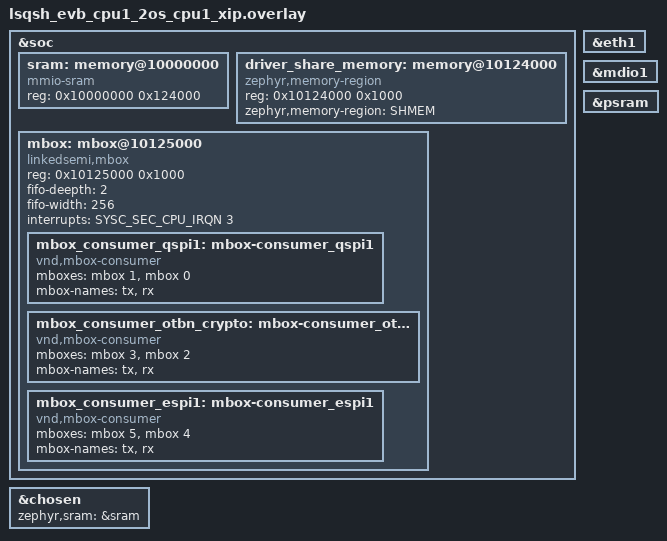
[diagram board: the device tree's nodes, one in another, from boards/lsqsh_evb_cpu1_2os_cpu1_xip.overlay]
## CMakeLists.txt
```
cmake_minimum_required(VERSION 3.20.0)

set(TOOLCHAIN_HAS_NEWLIB y)

find_package(Zephyr REQUIRED HINTS $ENV{ZEPHYR_BASE})

project(bmc_app LANGUAGES C CXX)

target_sources(app PRIVATE main.c
    dbus/sd-bus.c
    dbus/sd-event.c
    dbus/sd-journal.c
    misc.c)
zephyr_include_directories(inc)
zephyr_linker_sources(SECTIONS ipmid_section.ld)
```

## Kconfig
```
config INTERNAL_CONFIG
    bool
    default y
    select RISCV_ISA_EXT_F
    select CPU_HAS_FPU
    select FPU

source "Kconfig.zephyr"
```

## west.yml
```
manifest:

  remotes:
    - name: linkedsemi
      url-base: https://github.com/linkedsemi
  projects:
    - name: zephyr
      remote: linkedsemi
      revision: 9aba231538cb15e326d0b32fb71ca6ec78597236
      import:
        name-allowlist:
          - fatfs
          - littlefs
    - name: ls_sdk
      revision: 8e480881e7888d80db16ccb5c70e5a515f84650c
      remote: linkedsemi
      path: modules/hal/linkedsemi
      groups:
        - hal
    - name: mbedtls
      revision: a8be860ee1686013afd1fa27435d87b56c1f60d9
      remote: linkedsemi
      path: modules/crypto/mbedtls
      groups:
        - crypto
    - name: wolfssl
      revision: 89450e806ffa6cedd4f12fbf725acd990ac38320
      remote: linkedsemi
      path: modules/lib/wolfssl
    - name: wolfssh
      revision: fe25b4ef99eccb63ceec62f9948b6325dc279099
      remote: linkedsemi
      path: modules/lib/wolfssh
    - name: safeclib
      revision: 4e279a5254d7e443e3659fec95cf25ceaa4c8a27
      remote: linkedsemi
      path: modules/safeclib
    - name: jtag_asd
      revision: 9bf8e9ca6a7e28fb6f33758f0c463f358b16ad28
      remote: linkedsemi
      path: modules/jtag_asd
    - name: basu
      revision: 882fe5b94a8847edfe996d54bbfb0844d98a51d0
      remote: linkedsemi
      path: modules/lib/basu
    - name: dbus-broker
      revision: 393c86f08e7303c44ae71f3970fc29adf63d95c8
      remote: linkedsemi
      path: modules/lib/dbus-broker
    - name: nlohmann_json
      revision: 21d6a8608dd486b3bdc69b5f3f36f4c2e32ea462
      remote: linkedsemi
      path: openbmc/nlohmann_json
    - name: phosphor-host-ipmid
      revision: 730b99eceb20ac83a155bb5b3ebfe294fbad685a
      remote: linkedsemi
      path: openbmc/phosphor-host-ipmid
    - name: boost
      revision: ecb994e4dd073c20249af3570d365cce79d9095c
      remote: linkedsemi
      path: openbmc/boost
    - name: sdeventplus
      revision: b08defd63ee0cc1272ab325254607e02b27fb972
      remote: linkedsemi
      path: openbmc/sdeventplus
    - name: stdplus
      revision: e7e5ac6c2a5b0a7abdfca49fa8bdeea58451292d
      remote: linkedsemi
      path: openbmc/stdplus
    - name: fmt
      revision: 7efd053646053b98a7b4426e89f9661ba0de20e1
      remote: linkedsemi
      path: openbmc/fmt
    - name: function2
      revision: c06f8813e86649f7400046a25994d462fe5ff7b9
      remote: linkedsemi
      path: openbmc/function2
    - name: sdbusplus
      revision: 8509238c2e8602a706666208fbc088f3c9c3d326
      remote: linkedsemi
      path: openbmc/sdbusplus
    - name: phosphor-logging
      revision: 3238acdf4dbc14b1cb62a90739becdaf0bc66402
      remote: linkedsemi
      path: openbmc/phosphor-logging
    - name: phosphor-dbus-interfaces
      revision: b9c6138f7646f4cd10374600386552bf905eb68d
      remote: linkedsemi
      path: openbmc/phosphor-dbus-interfaces
    - name: phosphor-objmgr
      revision: 7d4eb7772eb67e8a57bb9dab55dfcbd362e3c6bb
      remote: linkedsemi
      path: openbmc/phosphor-objmgr
    - name: zephyr-osal
      revision: 47fe85a8680038272ac783a4ce8f4cdcb51b40a6
      remote: linkedsemi
      path: openbmc/zephyr-osal
    - name: tinyxml2
      revision: 19970f901fc80455e6fb5c15c26c197a6219578d
      remote: linkedsemi
      path: openbmc/tinyxml2
    - name: phosphor-net-ipmid
      revision: 245cd64dec52e85913267071df907d8395189934
      remote: linkedsemi
      path: openbmc/phosphor-net-ipmid
    - name: valijson
      revision: 94adf049ae196e127f3df0c18a1fefec9aa91ffd
      remote: linkedsemi
      path: openbmc/valijson
    - name: entity-manager
      revision: 3b91d98a54b7d59a5b8e6adf31a0a08fa84fd3d5
      remote: linkedsemi
      path: openbmc/entity-manager
    - name: i2c-tools
      revision: 0f412d81bb96408c383e7975b43cae2acab0199a
      remote: linkedsemi
      path: openbmc/i2c-tools
    - name: mk-rofs
      revision: a9d799835340258a4e0324e7b765dc860702b5a5
      remote: linkedsemi
      path: openbmc/mk-rofs
    - name: ipmitool
      revision: 0612d2f435143068074414a8bbdb54e7abf89e20
      remote: linkedsemi
      path: openbmc/ipmitool
    - name: kcsbridge
      revision: c75e6c1a14152f822f769fd8a38f691390cbfa2e
      remote: linkedsemi
      path: openbmc/kcsbridge
    - name: zephyr-devfs
      revision: a8cd40c478183bf0542fe570a45c07ee4688e513
      remote: linkedsemi
      path: openbmc/zephyr-devfs
    - name: dbus-sensors
      revision: 406c04ee7f4f0963600f638b2547e835e1ebf05a
      remote: linkedsemi
      path: openbmc/dbus-sensors
    - name: libgpiod
      revision: a75d5b0ff8d1554dd5bc5c78c2892b5d58dc28da
      remote: linkedsemi
      path: openbmc/libgpiod
    - name: cereal
      revision: b649d13a60f52f66a5c2f01b23ac5dac4ea703fb
      remote: linkedsemi
      path: openbmc/cereal
    - name: bmcweb
      revision: 933053b7a557adbb325d8f68f5d25c68a0ce82bf
      remote: linkedsemi
      path: openbmc/bmcweb
    - name: cli11
      revision: 94def1d7ee59c2ff2bb6b284c826e76cd1b1792a
      remote: linkedsemi
      path: openbmc/cli11
    - name: webui-vue
      revision: c2d6ca1c9c56700164f07434f7384c942c977059
      remote: linkedsemi
      path: openbmc/webui-vue
    - name: phosphor-bmc-code-mgt
      revision: 13d007b1e64cc597133381d6bc899c025264d0fe
      remote: linkedsemi
      path: openbmc/phosphor-bmc-code-mgt
    - name: miniz
      revision: 659f53cf6b6da3e7c5e2b3be0076b21ef154e787
      remote: linkedsemi
      path: modules/lib/miniz
    - name: phosphor-sel-logger
      revision: 5ce58ed2b2a734409daf32be078f2fdbf5f2fb6c
      remote: linkedsemi
      path: openbmc/phosphor-sel-logger
```

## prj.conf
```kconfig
######################################################
# COMMON CONFIGURATION
######################################################
CONFIG_NEWLIB_LIBC=y
CONFIG_FILE_SYSTEM=y
CONFIG_POSIX_API=y
CONFIG_EVENTFD=y
CONFIG_LOG=n
CONFIG_STATIC_INIT_GNU=y
CONFIG_TEST_RANDOM_GENERATOR=y
CONFIG_NETWORKING=y
CONFIG_NET_TCP=y
CONFIG_NET_SOCKETS=y
CONFIG_NET_SOCKETS_POLL_MAX=4
CONFIG_MAX_PTHREAD_MUTEX_COUNT=128


CONFIG_NET_ZPERF=y
# CONFIG_NET_LOG is not set
CONFIG_NET_UDP=y
# NET_IPV6=n 时该选项无依赖，置 n 避免 Kconfig 警告
CONFIG_NET_TCP_IPV6_ND_REACHABILITY_HINT=n
CONFIG_NET_STATISTICS=y
CONFIG_NET_STATISTICS_USER_API=y
CONFIG_NET_STATISTICS_IPV4=y
CONFIG_NET_STATISTICS_UDP=y
CONFIG_NET_STATISTICS_TCP=y
CONFIG_NET_STATISTICS_ETHERNET=y
CONFIG_NET_TC_TX_COUNT=1
CONFIG_NET_SOCKETS_SERVICE_THREAD_PRIO=-1
CONFIG_INIT_STACKS=y
CONFIG_NET_L2_ETHERNET=y

# Shell enabled with serial backend
CONFIG_SHELL=y
CONFIG_KERNEL_SHELL=y
CONFIG_SHELL_BACKEND_SERIAL=y
CONFIG_SHELL_THREAD_PRIORITY_OVERRIDE=y
CONFIG_NET_SHELL=y
CONFIG_SPEED_OPTIMIZATIONS=y

######################################################
# 网络配置（参考 zephyr_openbmc - 仅 IPv4）
######################################################
CONFIG_NET_IPV4=y
CONFIG_NET_IPV6=n


CONFIG_NET_CONFIG_SETTINGS=y
CONFIG_NET_CONFIG_AUTO_INIT=n
CONFIG_NET_CONFIG_INIT_TIMEOUT=120

CONFIG_NET_DHCPV4=y
CONFIG_NET_CONFIG_MY_IPV4_ADDR="192.0.2.13"
CONFIG_NET_CONFIG_MY_IPV4_NETMASK="255.255.255.0"
CONFIG_NET_CONFIG_MY_IPV4_GW=""


CONFIG_NET_IF_UNICAST_IPV4_ADDR_COUNT=2

# ARP 协议
CONFIG_NET_ARP=y
CONFIG_NET_ARP_GRATUITOUS=y
CONFIG_NET_ARP_GRATUITOUS_TRANSMISSION=y
CONFIG_NET_MGMT_EVENT_INFO=y

CONFIG_NET_IPV4_ACD=y



# CONFIG_NET_CORE_LOG_LEVEL_DBG=y
# CONFIG_NET_ARP_LOG_LEVEL_DBG=y
# CONFIG_NET_L2_ETHERNET_LOG_LEVEL_DBG=y
# CONFIG_NET_ICMPV4_LOG_LEVEL_DBG=y
# CONFIG_NET_IF_LOG_LEVEL_DBG=y
# CONFIG_NET_CONFIG_LOG_LEVEL_DBG=y


CONFIG_NET_TCP_WORKER_PRIO=10

# 网络管理
CONFIG_NET_MGMT=y
CONFIG_NET_MGMT_EVENT=y
CONFIG_NET_L2_ETHERNET_MGMT=y


CONFIG_NET_BUF_DATA_SIZE=256
CONFIG_NET_PKT_RX_COUNT=64
CONFIG_NET_PKT_TX_COUNT=64
CONFIG_NET_BUF_RX_COUNT=128
CONFIG_NET_BUF_TX_COUNT=128
CONFIG_NET_MAX_CONTEXTS=32
CONFIG_NET_MAX_CONN=32

# 网络栈大小配置
CONFIG_NET_TX_STACK_SIZE=2048
CONFIG_NET_RX_STACK_SIZE=2048
CONFIG_NET_MGMT_EVENT_STACK_SIZE=3072

CONFIG_NET_LOOPBACK=y


CONFIG_NET_IF_UNICAST_IPV4_ADDR_COUNT=2
CONFIG_NET_IF_MCAST_IPV4_ADDR_COUNT=1

CONFIG_NET_CONTEXT_RECV_PKTINFO=y

CONFIG_THREAD_NAME=y

CONFIG_TEST_AUTH=y
######################################################
# INET SOCKETS CONFIGURATION
######################################################
# CONFIG_NET_LOOPBACK=y
# CONFIG_NET_IPV4=y
# CONFIG_NET_SOCKETS_PACKET=y
# CONFIG_NET_MAX_CONTEXTS=32
# CONFIG_NET_MAX_CONN=32
# CONFIG_NET_PKT_RX_COUNT=64
# CONFIG_NET_PKT_TX_COUNT=64
# CONFIG_NET_BUF_RX_COUNT=128
# CONFIG_NET_BUF_TX_COUNT=128
######################################################
# INET SOCKETS CONFIGURATION END
######################################################


############################################
# UNIX SOCKET DBUS BROKER CONFIGURATION
#Test Target	SOCKETPOOL_SIZE	BUFFER_SIZE	HEAP_SIZE	Max Connections
# 10  clients	    16	            8192	  256KB	          ~10
# 20  clients	    32	            16384	  512KB	          ~20
# 50  clients	    64	            16384	   1MB	        ~40-50
# 100 clients	    128	            32768	   2MB	        ~80-100
############################################
CONFIG_PSRAM=y
CONFIG_NEWLIB_LIBC_MALLOC_SECTION_NAME="PSRAM"
CONFIG_NEWLIB_LIBC_MALLOC_LSQSH=y

CONFIG_SYS_HEAP_RUNTIME_STATS=y

CONFIG_NEWLIB_LIBC_MALLOC_ARENA_SIZE=5242880

CONFIG_MAIN_STACK_SIZE=102400
CONFIG_HEAP_MEM_POOL_SIZE=212992
CONFIG_POSIX_MAX_FDS=112
CONFIG_ZVFS_POLL_MAX=112
CONFIG_ZVFS_OPEN_MAX=80
CONFIG_NET_SOCKETPAIR=y
CONFIG_NET_SOCKETPAIR_BUFFER_SIZE=4096
######################################################
# DBUS SOCKET MODE SELECTION
######################################################
# Enable D-Bus broker subsystem
CONFIG_DBROKER=y
CONFIG_DBUS_BROKER_STACK_SIZE=6144
CONFIG_DBUS_BROKER_PRIORITY=7
# UNIX domain sockets
CONFIG_DBUS_BROKER_SOCKETPOOL=y
CONFIG_DBUS_BROKER_SOCKETPOOL_SIZE=16
CONFIG_DBUS_BROKER_SOCKETPOOL_BUFFER_SIZE=6144
# INET sockets
# CONFIG_DBUS_BROKER_INET=y
# CONFIG_DBUS_BROKER_PORT=55555

CONFIG_ASSERT=y

CONFIG_XIP=y
CONFIG_BOOT_CPU2=n
# CONFIG_THREAD_LOCAL_STORAGE=y
# CONFIG_LOG_DEFAULT_LEVEL=3
CONFIG_FRAME_POINTER=y
CONFIG_THREAD_LOCAL_STORAGE=y
CONFIG_TOOLCHAIN_CROSS_COMPILE_SUPPORTS_THREAD_LOCAL_STORAGE=y
CONFIG_POSIX_THREADS=y

CONFIG_ZVFS_OPEN_MAX=512
CONFIG_ZVFS_EVENTFD_MAX=512

CONFIG_CPP=y
CONFIG_STD_CPP20=y
CONFIG_REQUIRES_FULL_LIBCPP=y
CONFIG_CPP_EXCEPTIONS=y
CONFIG_TOOLCHAIN_CROSS_COMPILE_SUPPORTS_GNU_EXTENSIONS=y



CONFIG_POSIX_THREAD_THREADS_MAX=40
CONFIG_POSIX_TIMERS=y
CONFIG_XOPEN_STREAMS=y
CONFIG_CPP_RTTI=y

CONFIG_BASU=y
CONFIG_DBUS_BROKER=y
# CONFIG_NET_DEBUG=y
CONFIG_ZEPHYR_OSAL=y

CONFIG_NET_HOSTNAME="openbmc"
CONFIG_NET_HOSTNAME_DYNAMIC=y

CONFIG_OPENBMC_SDBUSPLUS=y

CONFIG_OPENBMC_PHOSPHOR_HOST_IPMID=y
CONFIG_OPENBMC_PHOSPHOR_NET_IPMID=y

CONFIG_OPENBMC_BOOST=y

CONFIG_OPENBMC_PHOSPHOR_LOGGING=y

CONFIG_OPENBMC_PHOSPHOR_OBJMGR=y

CONFIG_TINYXML2=y

CONFIG_WOLFSSL=y
CONFIG_WOLFSSL_SETTINGS_FILE="wolfssl_user_settings.h"

CONFIG_OPENBMC_PHOSPHOR_DBUS_INTERFACES=y

CONFIG_OPENBMC_SDEVENTPLUS=y



# debug config
# CONFIG_HW_STACK_PROTECTION=y
# CONFIG_PMP_STACK_GUARD_MIN_SIZE=2048
```

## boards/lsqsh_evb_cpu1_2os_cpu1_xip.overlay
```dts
&soc {
    /delete-node/ memory@100c0000;
    /delete-node/ memory@10100000;
    /delete-node/ memory@100be000;
    /delete-node/ mbox@100bf000;
    sram: memory@10000000 {
        compatible = "mmio-sram";
        reg = <0x10000000 0x124000>;
    };
    driver_share_memory: memory@10124000 {
        compatible = "zephyr,memory-region", "mmio-sram";
        reg = <0x10124000 0x1000>;
        zephyr,memory-region = "SHMEM";
    };
    mbox: mbox@10125000 {
        compatible = "linkedsemi,mbox";
        reg = <0x10125000 0x1000>;
        fifo-deepth = <2>;
        fifo-width = <256>;
        #mbox-cells = <1>;
        interrupts = <SYSC_SEC_CPU_IRQN 3>;
        status = "okay";
        mbox_consumer_qspi1: mbox-consumer_qspi1 {
            compatible = "vnd,mbox-consumer";
            mboxes = <&mbox 1>, <&mbox 0>;
            mbox-names = "tx", "rx";
        };
        mbox_consumer_otbn_crypto: mbox-consumer_otbn_crypto {
            compatible = "vnd,mbox-consumer";
            mboxes = <&mbox 3>, <&mbox 2>;
            mbox-names = "tx", "rx";
        };
        mbox_consumer_espi1: mbox-consumer_espi1 {
            compatible = "vnd,mbox-consumer";
            mboxes = <&mbox 5>, <&mbox 4>;
            mbox-names = "tx", "rx";
        };
    };
};


&chosen {
    zephyr,sram = &sram;
};

&eth1 {
    status = "okay";
};

&mdio1 {
    status = "okay";
};


&psram {
    status = "okay";
};
```

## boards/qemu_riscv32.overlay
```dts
/ {
	chosen {
		zephyr,uart_pipe = &uart0;
	};
};
```

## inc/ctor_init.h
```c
#ifndef CTOR_INIT_H_
#define CTOR_INIT_H_
#include <zephyr/sys/iterable_sections.h>
typedef void (*ctor_fn_t)();
#define CTOR_SECTION_ITERABLE(secname,func) \
    const static TYPE_SECTION_ITERABLE(ctor_fn_t,func##_ptr,secname,func##_ptr) = func;

#endif
```

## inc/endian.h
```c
#ifndef ENDIAN_H_
#define ENDIAN_H_
#include <stdint.h>

uint16_t htobe16(uint16_t host_16bits);
static inline uint16_t htole16(uint16_t host_16bits)
{
    return host_16bits;
}

uint16_t be16toh(uint16_t big_endian_16bits);
static inline uint16_t le16toh(uint16_t little_endian_16bits)
{
    return little_endian_16bits;
}

uint32_t htobe32(uint32_t host_32bits);

static inline uint32_t htole32(uint32_t host_32bits)
{
	return host_32bits;
}

uint32_t be32toh(uint32_t big_endian_32bits);
static uint32_t le32toh(uint32_t little_endian_32bits)
{
    return little_endian_32bits;
}

uint64_t htobe64(uint64_t host_64bits);
uint64_t htole64(uint64_t host_64bits);
uint64_t be64toh(uint64_t big_endian_64bits);
uint64_t le64toh(uint64_t little_endian_64bits);


#endif
```

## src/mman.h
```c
#ifndef ZEPHYR_MMAN_H
#define ZEPHYR_MMAN_H

#include <stddef.h>

/* Memory protection flags */
#ifndef PROT_READ
#define PROT_READ  0x1
#endif

#ifndef PROT_WRITE
#define PROT_WRITE 0x2
#endif

#ifndef PROT_EXEC
#define PROT_EXEC  0x4
#endif

#ifndef PROT_NONE
#define PROT_NONE  0x0
#endif

/* Mapping flags */
#ifndef MAP_SHARED
#define MAP_SHARED    0x01
#endif

#ifndef MAP_PRIVATE
#define MAP_PRIVATE   0x02
#endif

#ifndef MAP_FIXED
#define MAP_FIXED     0x10
#endif

#ifndef MAP_ANONYMOUS
#define MAP_ANONYMOUS 0x20
#endif

#ifndef MAP_FAILED
#define MAP_FAILED ((void *)-1)
#endif

/* Functions declared in basu_zephyr_compat.h and implemented in sys_compat.c */
#ifdef __ZEPHYR__
void *mmap(void *addr, size_t length, int prot, int flags, int fd, off_t offset);
int munmap(void *addr, size_t length);
#endif

#endif /* ZEPHYR_MMAN_H */
```

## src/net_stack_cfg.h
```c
/* SPDX-License-Identifier: Apache-2.0 */
#pragma once

#ifdef __cplusplus
extern "C" {
#endif

int net_stack_cfg_do_once(void);

#ifdef __cplusplus
}
#endif
```

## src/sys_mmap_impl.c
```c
/* SPDX-License-Identifier: Apache-2.0 */
#include <stdlib.h>
#include <errno.h>
#include <sys/types.h>

#ifndef MAP_FAILED
#define MAP_FAILED ((void *)-1)
#endif

#ifndef MAP_ANONYMOUS
#define MAP_ANONYMOUS 0x20
#endif

#ifndef off_t
typedef long off_t;
#endif

/* Simple mmap implementation for Zephyr using malloc/free */
void *mmap(void *addr, size_t length, int prot, int flags, int fd, off_t offset)
{
	void *ptr;

	/* Zephyr doesn't support file-backed mappings */
	if (!(flags & MAP_ANONYMOUS) && fd >= 0) {
		errno = ENOSYS;
		return MAP_FAILED;
	}

	/* Ignore addr parameter - always allocate new memory */
	(void)addr;
	(void)offset;
	(void)prot;

	/* Allocate memory */
	ptr = malloc(length);
	if (!ptr) {
		errno = ENOMEM;
		return MAP_FAILED;
	}

	return ptr;
}

/* Simple munmap implementation for Zephyr using free */
int munmap(void *addr, size_t length)
{
	(void)length;

	if (!addr) {
		errno = EINVAL;
		return -1;
	}

	free(addr);
	return 0;
}
```

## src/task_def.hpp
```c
#pragma once

#include <pthread.h>

#ifdef __cplusplus
extern "C" {
#endif

#ifdef CONFIG_QEMU_TARGET
#define THREAD_STACK_SECTION
#else
// #define THREAD_STACK_SECTION(name) __attribute__((section(".noinit" "." #name "." "stack")))
#define THREAD_STACK_SECTION(name) __attribute__((section(CONFIG_APP_STACK_SECTION "." #name "." "stack")))
#endif

int create_task_with_pthread(pthread_t *thread, const char *name,
                             void *stack, size_t stack_size,
                             void* (*routine)(void *), bool join_flag);

#define CREATE_TASK_WITH_PTHREAD(thread, name, stack_size) \
    static Z_KERNEL_STACK_DEFINE_IN(name##_stack, stack_size, THREAD_STACK_SECTION(name)); \
    create_task_with_pthread(thread, #name, name##_stack, stack_size, name##_handler, false);

#define CREATE_TASK_WITH_PTHREAD_JOIN(thread, name, stack_size) \
    static Z_KERNEL_STACK_DEFINE_IN(name##_stack, stack_size, THREAD_STACK_SECTION(name)); \
    create_task_with_pthread(thread, #name, name##_stack, stack_size, name##_handler, true);

//net config init
// extern struct k_sem net_config_init_ready_sem;

// zbus broker
#define CONFIG_THREAD_PRI_DBUS_BROKER 10
#define DBUS_BROKER_THREAD_STACK_SIZE (1 * 1024)
int dbus_broker_init();
extern struct k_sem dbus_broker_ready_sem;

// phosphor-host-ipmid
#define CONFIG_THREAD_PRI_IPMI 10
#define IPMI_THREAD_STACK_SIZE (32 * 1024)
int ipmid_init();
extern struct k_sem host_ipmid_ready_sem;

// busctl
#define CONFIG_THREAD_PRI_BUSCTL 10
#define BUSCTL_THREAD_STACK_SIZE (32 * 1024)
int busctl_init();
extern struct k_sem busctl_ready_sem;

// phosphor-watchdog
#define CONFIG_THREAD_PRI_WATCHDOG 10
#define WATCHDOG_THREAD_STACK_SIZE (32 * 1024)
int watchdog_init();
extern struct k_sem watchdog_ready_sem;

// phosphor-led-sysfs
#define CONFIG_THREAD_PRI_LED_SYSFS 10
#define LED_SYSFS_THREAD_STACK_SIZE (32 * 1024)
int led_sysfs_init();
extern struct k_sem led_sysfs_ready_sem;

// phosphor-led-manager
#define CONFIG_THREAD_PRI_LED_MANAGER 10
#define LED_MANAGER_THREAD_STACK_SIZE (32 * 1024)
int led_manager_init();
extern struct k_sem led_manager_ready_sem;

// phosphor-settings
#define CONFIG_THREAD_PRI_SETTING_MANAGER 10
#define SETTING_MANAGER_THREAD_STACK_SIZE (32 * 1024)
int setting_manager_init();
extern struct k_sem setting_manager_ready_sem;

// phosphor-network
#define CONFIG_THREAD_PRI_NETWORK_MANAGER 10
#define NETWORK_MANAGER_THREAD_STACK_SIZE (32 * 1024)
int network_manager_init();
extern struct k_sem network_manager_ready_sem;

//ipmbbridge
#define CONFIG_THREAD_PRI_IPMBBRIDGE 10
#define IPMBBRIDGE_THREAD_STACK_SIZE (32 * 1024)
int ipmbbridge_init();
extern struct k_sem ipmbbridge_ready_sem;

//obmc_console
#define CONFIG_THREAD_PRI_OBMC_CONSOLE 10
#define OBMC_CONSOLE_THREAD_STACK_SIZE (32 * 1024)
int obmc_console_init();
extern struct k_sem obmc_console_ready_sem;

//timedated
#define CONFIG_THREAD_PRI_TIME_DATED 10
#define TIME_DATED_THREAD_STACK_SIZE (32 * 1024)
int timedated_init();
extern struct k_sem timedated_ready_sem;

//time-manager
#define CONFIG_THREAD_PRI_TIME_MANAGER 10
#define TIME_MANAGER_THREAD_STACK_SIZE (32 * 1024)
int time_manager_init();
extern struct k_sem time_manager_ready_sem;

//bios-setting-manager
#define CONFIG_THREAD_PRI_BIOS_SETTINGS_MGR 10
#define BIOS_SETTINGS_MGR_THREAD_STACK_SIZE (32 * 1024)
int bios_settings_mgr_init();
extern struct k_sem bios_settings_ready_sem;

//ipmitool
#define CONFIG_THREAD_PRI_IPMITOOL 10
#define IPMITOOL_THREAD_STACK_SIZE (32 * 1024)
int ipmitool_init();
extern struct k_sem ipmitool_ready_sem;

//user_manager
#define CONFIG_THREAD_PRI_USER_MANAGER 10
#define USER_MANAGER_THREAD_STACK_SIZE (32 * 1024)
int user_manager_init();
extern struct k_sem user_manager_ready_sem;

// net_stack_cfg - 网络栈配置（必须在 net-ipmid 之前初始化）
#define CONFIG_THREAD_PRI_NET_STACK_CFG 5
#define NET_STACK_CFG_THREAD_STACK_SIZE (16 * 1024)
int net_stack_cfg_init();
extern struct k_sem net_stack_cfg_ready_sem;

// phosphor-net-ipmid
#define CONFIG_THREAD_PRI_NET_IPMID 10
#define NET_IPMID_THREAD_STACK_SIZE (64 * 1024)
int net_ipmid_init();
extern struct k_sem net_ipmid_ready_sem;

//bmcweb
#define CONFIG_THREAD_PRI_BMCWEB 10
#define BMCWEB_THREAD_STACK_SIZE (32 * 1024)
int bmcweb_init();
extern struct k_sem bmcweb_ready_sem;

// phosphor-objmgr
#define CONFIG_THREAD_PRI_OBJMGR 10
#define OBJMGR_THREAD_STACK_SIZE (32 * 1024)
int objmgr_init();
extern struct k_sem objmgr_ready_sem;

// phosphor-bmc-code-mgt
#define CONFIG_THREAD_PRI_UPDATER 10
#define UPDATER_THREAD_STACK_SIZE (32 * 1024)
int software_updater_init();
extern struct k_sem software_updater_ready_sem;

#define CONFIG_THREAD_PRI_IMAGE 10
#define IMAGE_THREAD_STACK_SIZE (20 * 1024)
int image_manager_init();
extern struct k_sem image_manager_ready_sem;

//adcsensors
#define CONFIG_THREAD_PRI_ADC_SENSOR 10
#define ADC_SENSOR_THREAD_STACK_SIZE (32 * 1024)
int adc_sensor_init();
extern struct k_sem adc_sensor_ready_sem;

// phosphor-logging
#define CONFIG_THREAD_PRI_LOGGING 10
#define PHOSPHOR_LOGGING_THREAD_STACK_SIZE (32 * 1024)
int logging_init();
extern struct k_sem logging_ready_sem;

#define CONFIG_THREAD_PRI_EXTERNAL_SENSOR 10
#define EXTERNAL_SENSOR_THREAD_STACK_SIZE (32 * 1024)
int external_sensor_init();
extern struct k_sem external_sensor_ready_sem;

#define CONFIG_THREAD_PRI_FAN_SENSOR 10
#define FAN_SENSOR_THREAD_STACK_SIZE (32 * 1024)
int fan_sensor_init();
extern struct k_sem fan_sensor_ready_sem;

#define CONFIG_THREAD_PRI_HWMON_TEMP_SENSOR 10
#define HWMON_TEMP_SENSOR_THREAD_STACK_SIZE (32 * 1024)
int hwmon_temp_sensor_init();
extern struct k_sem hwmon_temp_sensor_ready_sem;

#define CONFIG_THREAD_PRI_INTEL_CPU_SENSOR 10
#define INTEL_CPU_SENSOR_THREAD_STACK_SIZE (32 * 1024)
int intel_cpu_sensor_init();
extern struct k_sem intel_cpu_sensor_ready_sem;

#define CONFIG_THREAD_PRI_INTRUSION_SENSOR 10
#define INTRUSION_SENSOR_THREAD_STACK_SIZE (32 * 1024)
int intrusion_sensor_init();
extern struct k_sem intrusion_sensor_ready_sem;

#define CONFIG_THREAD_PRI_PSU_SENSOR 10
#define PSU_SENSOR_THREAD_STACK_SIZE (32 * 1024)
int psu_sensor_init();
extern struct k_sem psu_sensor_ready_sem;

// phosphor-sel-logger
#define CONFIG_THREAD_PRI_SEL_LOGGER 10
#define SEL_LOGGER_THREAD_STACK_SIZE (32 * 1024)
int sel_logger_init();
extern struct k_sem sel_logger_ready_sem;

// phosphor-state-manager
#define CONFIG_THREAD_PRI_BMC_STATE 10
#define BMC_STATE_THREAD_STACK_SIZE (32 * 1024)
int bmc_state_init();
extern struct k_sem bmc_state_ready_sem;

// phosphor-debug-collector
#define CONFIG_THREAD_PRI_DUMP_MANAGER 10
#define DUMP_MANAGER_THREAD_STACK_SIZE (32 * 1024)
int dump_manager_init();
extern struct k_sem dump_manager_ready_sem;

// systemd-networkd
#define CONFIG_THREAD_PRI_SYSTEMD_NETWORKD 10
#define SYSTEMD_NETWORKD_THREAD_STACK_SIZE (32 * 1024)
int systemd_networkd_init();
extern struct k_sem systemd_networkd_ready_sem;

#define CONFIG_THREAD_PRI_ENTITY 10
#define ENTITY_MANAGER_THREAD_STACK_SIZE (20 * 1024)
int entity_manager_init();
extern struct k_sem entity_manager_ready_sem;

#define CONFIG_THREAD_PRI_FRU 10
#define FRU_DEVICE_THREAD_STACK_SIZE (12 * 1024)
int fru_device_init();
extern struct k_sem fru_device_ready_sem;

#define CONFIG_THREAD_PRI_CALLBACK_MANAGER 10
#define CALLBACK_MANAGER_THREAD_STACK_SIZE (32 * 1024)
int callback_manager_init();
extern struct k_sem callback_manager_ready_sem;

#define CONFIG_THREAD_PRI_PHOSPHOR_HOSTLOGGER 10
#define PHOSPHOR_HOSTLOGGER_THREAD_STACK_SIZE 64 * 1024)
int phosphor_hostlogger_init();
extern struct k_sem phosphor_hostlogger_ready_sem;

//kcs bridge
#define CONFIG_THREAD_PRI_KCS_BRIDGE 10
#define KCS_BRIDGE_THREAD_STACK_SIZE (32 * 1024)
int kcs_bridge_init();
extern struct k_sem kcs_bridge_ready_sem;

//certificate manager
#define CONFIG_THREAD_PRI_CERTIFICATE_MANAGER 10
#define CERTIFICATE_MANAGER_THREAD_STACK_SIZE (20 * 1024)
int certificate_manager_init();
extern struct k_sem certificate_manager_ready_sem;

//i2ctest
int i2ctest_init();
//kcstest
int kcstest_init();
//eepromtest
int eepromtest_init();
//gpiotest
int gpiotest_init();
//ledtest
int ledtest_init();
//uarttest
int uarttest_init();
//hwmontest
int hwmontest_init();

#ifdef __cplusplus
}
#endif
```

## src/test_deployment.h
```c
/*
 * test_deployment.h - Standard Broker Deployment Interface
 */

#ifndef TEST_DEPLOYMENT_H
#define TEST_DEPLOYMENT_H

#ifdef __cplusplus
extern "C" {
#endif

/* Main deployment function using broker_run() */
int run_broker_deployment(void);

/* Test function to verify deployment */
int test_broker_deployment(void);

int add_listener_to_broker(int listener_fd);
int create_listener_socket_with_retry(void);
int setup_controller_bus(void);

/* External variables for broker communication */
extern int g_controller_fds[2];
extern Broker *g_broker;

/* Function to start client threads */
int start_client_threads(void);

struct deployment_state {
    struct k_mutex lock;
    bool broker_ready;
    int listener_fd;
    bool service_provider_ready;
};

#ifdef __cplusplus
}
#endif

#endif /* TEST_DEPLOYMENT_H */
```

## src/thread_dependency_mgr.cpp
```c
#include "thread_dependency_mgr.hpp"

#include <string.h>
#include <zephyr/logging/log.h>

LOG_MODULE_DECLARE(TEST_BROKER, LOG_LEVEL_DBG);

// Thread registry
#define MAX_THREADS 64
static thread_descriptor_t *registered_threads[MAX_THREADS];
static int registered_thread_count = 0;
static struct k_mutex thread_registry_mutex;
static bool registry_initialized = false;

// Initialize registry
static void init_registry(void)
{
    if (!registry_initialized) {
        k_mutex_init(&thread_registry_mutex);
        registry_initialized = true;
    }
}

// Data structures for circular dependency detection
#define MAX_CALL_STACK_DEPTH 32
static const char *call_stack[MAX_CALL_STACK_DEPTH];
static int call_stack_depth = 0;
static struct k_mutex call_stack_mutex;
static bool call_stack_initialized = false;

// Initialize call stack mutex
static void init_call_stack(void)
{
    if (!call_stack_initialized) {
        k_mutex_init(&call_stack_mutex);
        call_stack_initialized = true;
    }
}

// Check for circular dependencies
static bool is_circular_dependency(const char *thread_name)
{
    for (int i = 0; i < call_stack_depth; i++) {
        if (strcmp(call_stack[i], thread_name) == 0) {
            return true;
        }
    }
    return false;
}

// Add to call stack
static bool push_call_stack(const char *thread_name)
{
    if (call_stack_depth >= MAX_CALL_STACK_DEPTH) {
        LOG_ERR("Error: Call stack overflow (max depth: %d)", MAX_CALL_STACK_DEPTH);
        return false;
    }
    call_stack[call_stack_depth++] = thread_name;
    return true;
}

// Remove from call stack
static void pop_call_stack(void)
{
    if (call_stack_depth > 0) {
        call_stack_depth--;
    }
}

void register_thread_descriptor(thread_descriptor_t *desc, const char **deps, int dep_count)
{
    init_registry();

    k_mutex_lock(&thread_registry_mutex, K_FOREVER);

    if (registered_thread_count < MAX_THREADS) {
        // Initialize dependency count
        desc->dependency_count = 0;

        // Special handling: validate dependency array
        if (dep_count > 0 && deps != nullptr) {
            int valid_deps = 0;
            for (int i = 0; i < dep_count && i < MAX_DEPENDENCIES; i++) {
                // Check if dependency is valid (not null and not empty string)
                if (deps[i] != nullptr && strlen(deps[i]) > 0) {
                    desc->dependencies[valid_deps] = deps[i];
                    valid_deps++;
                } else {
                    // Stop processing on invalid dependency
                    LOG_WRN("Warning: Invalid dependency at index %d for "
                        "thread %s",
                        i, desc->name);
                    break;
                }
            }
            desc->dependency_count = valid_deps;

            // Verify calculated dependency count matches actual valid dependencies
            if (dep_count != valid_deps) {
                LOG_WRN("Warning: Calculated dep_count (%d) differs from valid "
                    "deps (%d) for thread %s",
                    dep_count, valid_deps, desc->name);
            }
        }

        registered_threads[registered_thread_count++] = desc;
        LOG_INF("Registered thread: %s with %d dependencies", desc->name,
            desc->dependency_count);

        // Print dependencies
        for (int i = 0; i < desc->dependency_count; i++) {
            LOG_INF("  - depends on: %s", desc->dependencies[i]);
        }
    } else {
        LOG_ERR("Error: Too many threads registered (max: %d)", MAX_THREADS);
    }

    k_mutex_unlock(&thread_registry_mutex);
}

// Find thread descriptor
thread_descriptor_t *find_thread_descriptor(const char *name)
{
    init_registry();

    k_mutex_lock(&thread_registry_mutex, K_FOREVER);

    thread_descriptor_t *result = nullptr;
    for (int i = 0; i < registered_thread_count; i++) {
        if (strcmp(registered_threads[i]->name, name) == 0) {
            result = registered_threads[i];
            break;
        }
    }

    k_mutex_unlock(&thread_registry_mutex);
    return result;
}

// Check if thread dependencies are satisfied
bool check_thread_dependencies(const char *thread_name)
{
    thread_descriptor_t *desc = find_thread_descriptor(thread_name);
    if (!desc) {
        LOG_ERR("Error: Thread '%s' not found", thread_name);
        return false;
    }

    // Check all dependencies
    for (int i = 0; i < desc->dependency_count; i++) {
        thread_descriptor_t *dep_desc = find_thread_descriptor(desc->dependencies[i]);
        if (!dep_desc) {
            LOG_ERR("Error: Dependency '%s' for thread '%s' not found",
                  desc->dependencies[i], thread_name);
            return false;
        }

        if (dep_desc->state != THREAD_STATE_READY) {
            LOG_INF("Dependency '%s' for thread '%s' not ready (state: %d)",
                desc->dependencies[i], thread_name, dep_desc->state);
            return false;
        }
    }

    return true;
}

// Wait for dependency thread to become ready
static int wait_for_dependency_ready(thread_descriptor_t *dep_desc, const char *dep_name,
                     int timeout_s)
{
    if (dep_desc->state == THREAD_STATE_READY) {
        return 0;
    }

    if (dep_desc->state == THREAD_STATE_RUNNING) {
        if (dep_desc->ready_sem) {
            LOG_INF("Waiting for thread '%s' to be ready (timeout: %ds)...", dep_name,
                timeout_s);
            int ret = k_sem_take(dep_desc->ready_sem, K_SECONDS(timeout_s));
            if (ret == 0) {
                LOG_INF("Thread '%s' is ready", dep_name);
                return 0;
            } else {
                LOG_ERR("Error: Timeout waiting for thread '%s' to be ready",
                      dep_name);
                return -1;
            }
        } else {
            LOG_INF("Warning: Thread '%s' has no ready semaphore, assuming ready",
                dep_name);
            return 0;
        }
    } else if (dep_desc->state == THREAD_STATE_FAILED) {
        LOG_ERR("Error: Dependency thread '%s' is in FAILED state", dep_name);
        return -1;
    } else {
        LOG_ERR("Error: Dependency thread '%s' is in invalid state %d", dep_name,
              dep_desc->state);
        return -1;
    }
}

// Start a single thread and its dependencies
int start_thread_with_dependencies(const char *thread_name)
{
    if (!thread_name) {
        LOG_ERR("Error: thread_name is NULL");
        return -1;
    }

    init_call_stack();

    // Acquire call stack lock to prevent concurrent access
    k_mutex_lock(&call_stack_mutex, K_FOREVER);

    // Check for circular dependencies
    if (is_circular_dependency(thread_name)) {
        LOG_ERR("Error: Circular dependency detected for thread '%s'", thread_name);
        LOG_ERR("Call stack: ");
        for (int i = 0; i < call_stack_depth; i++) {
            LOG_ERR("%s -> ", call_stack[i]);
        }
        LOG_ERR("%s", thread_name);
        k_mutex_unlock(&call_stack_mutex);
        return -1;
    }

    // Add to call stack
    if (!push_call_stack(thread_name)) {
        k_mutex_unlock(&call_stack_mutex);
        return -1;
    }

    k_mutex_unlock(&call_stack_mutex);

    // Find thread descriptor
    thread_descriptor_t *desc = find_thread_descriptor(thread_name);
    if (!desc) {
        LOG_ERR("Error: Thread '%s' not found", thread_name);
        k_mutex_lock(&call_stack_mutex, K_FOREVER);
        pop_call_stack();
        k_mutex_unlock(&call_stack_mutex);
        return -1;
    }

    LOG_INF("Processing thread '%s' (deps: %d, state: %d)", desc->name, desc->dependency_count,
        desc->state);

    // If already started or starting, return immediately
    if (desc->state == THREAD_STATE_READY || desc->state == THREAD_STATE_RUNNING) {
        k_mutex_lock(&call_stack_mutex, K_FOREVER);
        pop_call_stack();
        k_mutex_unlock(&call_stack_mutex);
        return 0;
    }

    // Do not restart if failed
    if (desc->state == THREAD_STATE_FAILED) {
        LOG_ERR("Error: Thread '%s' is in FAILED state", thread_name);
        k_mutex_lock(&call_stack_mutex, K_FOREVER);
        pop_call_stack();
        k_mutex_unlock(&call_stack_mutex);
        return -1;
    }

    int ret = 0;

    // Recursively start dependencies
    for (int i = 0; i < desc->dependency_count; i++) {
        const char *dep_name = desc->dependencies[i];

        LOG_INF("Starting dependency '%s' for thread '%s'", dep_name, thread_name);

        ret = start_thread_with_dependencies(dep_name);
        if (ret != 0) {
            LOG_ERR("Error: Failed to start dependency '%s' for thread '%s'",
                  dep_name, thread_name);
            goto cleanup;
        }

        // Wait for dependency to actually become ready
        thread_descriptor_t *dep_desc = find_thread_descriptor(dep_name);
        if (!dep_desc) {
            LOG_ERR("Error: Dependency thread '%s' not found", dep_name);
            ret = -1;
            goto cleanup;
        }

        // Wait for dependency to be ready (100 seconds timeout)
        ret = wait_for_dependency_ready(dep_desc, dep_name, 100);
        if (ret != 0) {
            LOG_ERR("Error: Dependency '%s' failed to become ready", dep_name);
            goto cleanup;
        }
    }

    // Start current thread
    LOG_INF("Starting thread '%s'...", thread_name);

    ret = desc->init_func();
    if (ret == 0) {
        desc->state = THREAD_STATE_RUNNING;
        // Wait for thread to signal readiness
        if (desc->ready_sem) {
            int sem_ret =
                k_sem_take(desc->ready_sem, K_SECONDS(100)); // 100 seconds timeout
            if (sem_ret == 0) {
                desc->state = THREAD_STATE_READY;
                LOG_INF("Thread '%s' started successfully", thread_name);
            } else {
                LOG_ERR("Error: Timeout waiting for thread '%s' ready signal",
                      thread_name);
                desc->state = THREAD_STATE_FAILED;
                ret = -1;
            }
        } else {
            // Without semaphore, set ready directly
            desc->state = THREAD_STATE_READY;
            LOG_INF("Thread '%s' started successfully (no semaphore)", thread_name);
        }
    } else {
        desc->state = THREAD_STATE_FAILED;
        LOG_ERR("Error: Thread '%s' failed to start (ret: %d)", thread_name, ret);
    }

cleanup:
    // Clean up call stack
    k_mutex_lock(&call_stack_mutex, K_FOREVER);
    pop_call_stack();
    k_mutex_unlock(&call_stack_mutex);

    return ret;
}

// Start all auto-start threads
int start_all_auto_threads(void)
{
    init_registry();

    LOG_INF("Starting all auto-start threads...");

    int failed_count = 0;
    for (int i = 0; i < registered_thread_count; i++) {
        thread_descriptor_t *desc = registered_threads[i];
        if (desc->auto_start && desc->state == THREAD_STATE_INITIAL) {
            int ret = start_thread_with_dependencies(desc->name);
            if (ret != 0) {
                failed_count++;
                LOG_ERR("Failed to start thread '%s'", desc->name);
            }
        }
    }

    if (failed_count == 0) {
        LOG_INF("All auto-start threads started successfully");
    } else {
        LOG_WRN("Warning: %d threads failed to start", failed_count);
    }

    return failed_count;
}

// Print thread status
void print_thread_status(void)
{
    init_registry();

    LOG_INF("\n=== Thread Status ===");
    for (int i = 0; i < registered_thread_count; i++) {
        thread_descriptor_t *desc = registered_threads[i];
        const char *state_str;

        switch (desc->state) {
        case THREAD_STATE_INITIAL:
            state_str = "INITIAL";
            break;
        case THREAD_STATE_RUNNING:
            state_str = "STARTING";
            break;
        case THREAD_STATE_READY:
            state_str = "READY";
            break;
        case THREAD_STATE_FAILED:
            state_str = "FAILED";
            break;
        default:
            state_str = "UNKNOWN";
            break;
        }

        LOG_INF("Thread: %-20s State: %-8s Auto: %s", desc->name, state_str,
            desc->auto_start ? "YES" : "NO");

        // Print dependency count and details
        LOG_INF("  Dependencies Count: %d", desc->dependency_count);
    }
    LOG_INF("=====================\n");
}
```

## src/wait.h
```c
#ifndef ZEPHYR_WAIT_H
#define ZEPHYR_WAIT_H

/* Process status macros for wait/waitpid */
#ifndef WIFEXITED
#define WIFEXITED(status) (((status) & 0x7f) == 0)
#endif

#ifndef WEXITSTATUS
#define WEXITSTATUS(status) (((status) >> 8) & 0xff)
#endif

#ifndef WIFSIGNALED
#define WIFSIGNALED(status) (!WIFEXITED(status) && !WIFSTOPPED(status))
#endif

#ifndef WTERMSIG
#define WTERMSIG(status) ((status) & 0x7f)
#endif

#ifndef WIFSTOPPED
#define WIFSTOPPED(status) (((status) & 0xff) == 0x7f)
#endif

#ifndef WSTOPSIG
#define WSTOPSIG(status) (((status) >> 8) & 0xff)
#endif

#ifndef WNOHANG
#define WNOHANG 1
#endif

#ifndef WUNTRACED
#define WUNTRACED 2
#endif

/* Function declarations */
#ifdef __ZEPHYR__
pid_t wait(int *status);
pid_t waitpid(pid_t pid, int *status, int options);
#endif

#endif /* ZEPHYR_WAIT_H */
```

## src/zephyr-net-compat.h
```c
/*
 * Compatibility header for Zephyr network functions
 *
 * When CONFIG_USERSPACE is disabled, the syscall wrappers are not available.
 * This header provides macros to map net_addr_pton/net_addr_ntop to their
 * implementation functions (z_impl_net_addr_pton/z_impl_net_addr_ntop).
 *
 * SPDX-License-Identifier: Apache-2.0
 */

#ifndef ZEPHYR_NET_COMPAT_H
#define ZEPHYR_NET_COMPAT_H

/* Workaround for missing syscall wrappers when CONFIG_USERSPACE=n */
#ifndef CONFIG_USERSPACE
#define net_addr_pton(family, src, dst) z_impl_net_addr_pton(family, src, dst)
#define net_addr_ntop(family, src, dst, size) z_impl_net_addr_ntop(family, src, dst, size)
#endif

#endif /* ZEPHYR_NET_COMPAT_H */
```
